# NUC122_v1 register map
File version: 1.0
Registers are 32-bit, read-write, reset 0x0 unless marked. A register's access mark holds for its fields unless they carry their own. Offsets are from the block's base; [hi:lo] are bit positions; 'fields as' and 'values as' point back to an identical list.

## TMR01 — TMR Register Map
Base 0x40010000
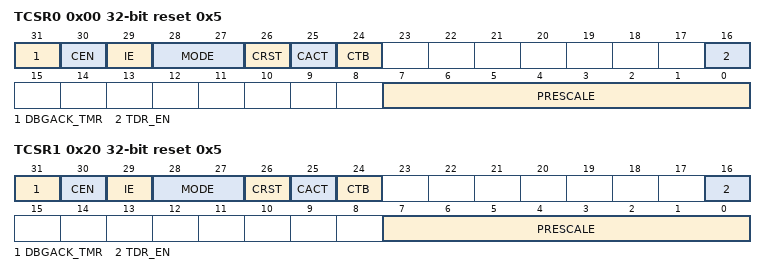
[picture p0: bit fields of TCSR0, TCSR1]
0x00 TCSR0 reset 0x5 — Timer0 Control and Status Register
  [31] DBGACK_TMR — ICE Debug Mode Acknowledge Disable (write-protection bit). TIMER counter will keep going no matter CPU is held by ICE or not.
    0=ICE debug mode acknowledgement effects TIMER counting; 1=ICE debug mode acknowledgement disabled
  [30] CEN — Timer Enable Bit
    0=Stops/Suspends counting; 1=Starts counting
  [29] IE — Interrupt Enable Bit. If timer interrupt is enabled, the timer asserts its interrupt signal (TIF) when the associated up-timer value is equal to TCMPR.
    0=Timer Interrupt Disabled; 1=Timer Interrupt Enabled
  [28:27] MODE — Timer Operating Mode
  [26] CRST — Timer Reset Bit. Setting this bit will reset the 24-bit up counter value (TDR) and also force CEN (TCSR[30] timer enable bit) to 0 if CACT (TCSR[25] timer active status bit) is 1.
    0=No effect; 1=Reset 8-bit pre-scale counter, 24-bit up counter value and CEN bit
  [25] CACT ro — Timer Active Status Bit (Read only). This bit indicates the 24-bit up counter status.
    0=24-bit up counter is not active; 1=24-bit up counter is active
  [24] CTB — Counter Mode Enable Bit. This bit is for external counting pin function enabled. When timer is used as an event counter, this bit should be set to 1 and select HCLK as timer clock source. Please refer to 5.10.4.5 for detail description.
    0=External counter mode Disabled; 1=External counter mode Enabled
  [16] TDR_EN — Data Load Enable. When this bit is set, timer counter value (TDR) will be updated continuously to monitor internal 24-bit up counter value as the counter is counting.
    0=Timer Data Register update Disabled; 1=Timer Data Register update Enabled while timer counter is active
  [7:0] PRESCALE — Pre-scale Counter
0x04 TCMPR0 — Timer0 Compare Register
  [23:0] TCMP — Timer Compared Value. TCMP is a 24-bit compared value register. When the internal 24-bit up counter value is equal to TCMP value, the TIF (TISR[0] timet interrupt flag) will set to 1. Note1: Never write 0x0 or 0x1 in TCMP field, or the core will run into unknown state. Note2: When timer is operating at continuous counting mode, the 24-bit up counter will keep counting continuously even if software writes a new value into TCMP field. But if timer is operating at other modes, the 24-bit up counter will restart counting and using newest TCMP value to be the timer compared value if software writes a new value into TCMP field.
0x08 TISR0 — Timer0 Interrupt Status Register
  [0] TIF — Timer Interrupt Flag. This bit indicates the interrupt flag status of Timer. And this bit is set by hardware when the timer counter value) matches the timer compared value (TCMP value). It is cleared by writing 1 to it through software.
0x0C TDR0 ro — Timer0 Data Register
  [23:0] TDR — Timer Data Register. When TCSR.TDR_EN is set to 1, the internal 24-bit up-timer value will be loaded into TDR. User can read this register for the up-timer value.
0x20 TCSR1 reset 0x5 — Timer1 Control and Status Register
  fields as TCSR0
0x24 TCMPR1 — Timer1 Compare Register
  fields as TCMPR0
0x28 TISR1 — Timer1 Interrupt Status Register
  fields as TISR0
0x2C TDR1 ro — Timer1 Data Register
  fields as TDR0

## TMR23 — TMR Register Map
Base 0x40110000
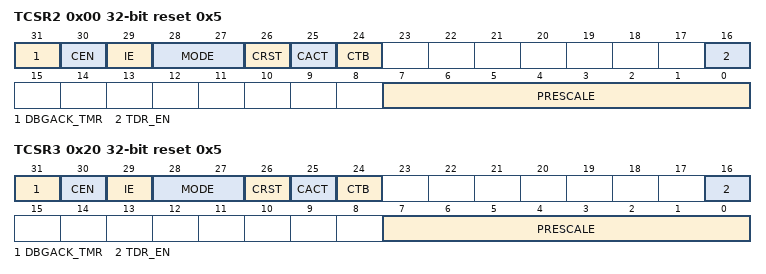
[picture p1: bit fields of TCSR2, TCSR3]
0x00 TCSR2 reset 0x5 — Timer2 Control and Status Register
  [31] DBGACK_TMR — ICE Debug Mode Acknowledge Disable (write-protection bit). TIMER counter will keep going no matter CPU is held by ICE or not.
    0=ICE debug mode acknowledgement effects TIMER counting; 1=ICE debug mode acknowledgement disabled
  [30] CEN — Timer Enable Bit
    0=Stops/Suspends counting; 1=Starts counting
  [29] IE — Interrupt Enable Bit. If timer interrupt is enabled, the timer asserts its interrupt signal (TIF) when the associated up-timer value is equal to TCMPR.
    0=Timer Interrupt Disabled; 1=Timer Interrupt Enabled
  [28:27] MODE — Timer Operating Mode
  [26] CRST — Timer Reset Bit. Setting this bit will reset the 24-bit up counter value (TDR) and also force CEN (TCSR[30] timer enable bit) to 0 if CACT (TCSR[25] timer active status bit) is 1.
    0=No effect; 1=Reset 8-bit pre-scale counter, 24-bit up counter value and CEN bit
  [25] CACT ro — Timer Active Status Bit (Read only). This bit indicates the 24-bit up counter status.
    0=24-bit up counter is not active; 1=24-bit up counter is active
  [24] CTB — Counter Mode Enable Bit. This bit is for external counting pin function enabled. When timer is used as an event counter, this bit should be set to 1 and select HCLK as timer clock source. Please refer to 5.10.4.5 for detail description.
    0=External counter mode Disabled; 1=External counter mode Enabled
  [16] TDR_EN — Data Load Enable. When this bit is set, timer counter value (TDR) will be updated continuously to monitor internal 24-bit up counter value as the counter is counting.
    0=Timer Data Register update Disabled; 1=Timer Data Register update Enabled while timer counter is active
  [7:0] PRESCALE — Pre-scale Counter
0x04 TCMPR2 — Timer2 Compare Register
  [23:0] TCMP — Timer Compared Value. TCMP is a 24-bit compared value register. When the internal 24-bit up counter value is equal to TCMP value, the TIF (TISR[0] timet interrupt flag) will set to 1. Note1: Never write 0x0 or 0x1 in TCMP field, or the core will run into unknown state. Note2: When timer is operating at continuous counting mode, the 24-bit up counter will keep counting continuously even if software writes a new value into TCMP field. But if timer is operating at other modes, the 24-bit up counter will restart counting and using newest TCMP value to be the timer compared value if software writes a new value into TCMP field.
0x08 TISR2 — Timer2 Interrupt Status Register
  [0] TIF — Timer Interrupt Flag. This bit indicates the interrupt flag status of Timer. And this bit is set by hardware when the timer counter value) matches the timer compared value (TCMP value). It is cleared by writing 1 to it through software.
0x0C TDR2 ro — Timer2 Data Register
  [23:0] TDR — Timer Data Register. When TCSR.TDR_EN is set to 1, the internal 24-bit up-timer value will be loaded into TDR. User can read this register for the up-timer value.
0x20 TCSR3 reset 0x5 — Timer3 Control and Status Register
  fields as TCSR2
0x24 TCMPR3 — Timer3 Compare Register
  fields as TCMPR2
0x28 TISR3 — Timer3 Interrupt Status Register
  fields as TISR2
0x2C TDR3 ro — Timer3 Data Register
  fields as TDR2
